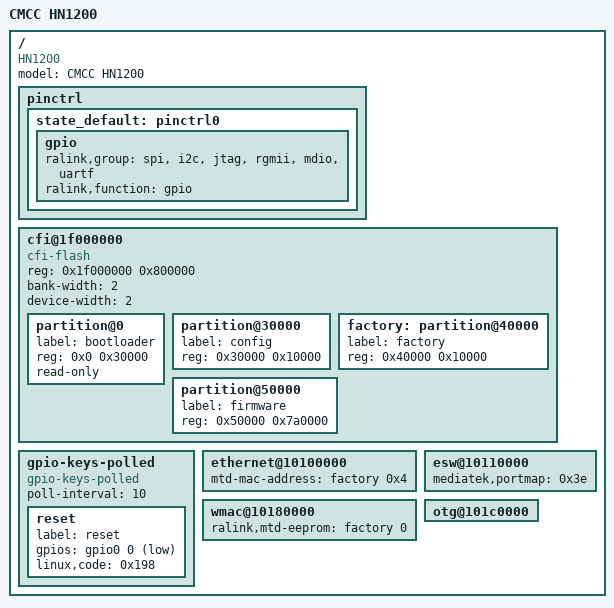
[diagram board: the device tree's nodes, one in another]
/dts-v1/;

/include/ "rt3050.dtsi"

/ {
	compatible = "HN1200", "ralink,rt3050-soc";
	model = "CMCC HN1200";

	pinctrl {
		state_default: pinctrl0 {
			gpio {
				ralink,group = "spi", "i2c", "jtag", "rgmii", "mdio", "uartf";
				ralink,function = "gpio";
			};
		};
	};

	cfi@1f000000 {
		compatible = "cfi-flash";
		reg = <0x1f000000 0x800000>;

		bank-width = <2>;
		device-width = <2>;
		#address-cells = <1>;
		#size-cells = <1>;

		partition@0 {
			label = "bootloader";
			reg = <0x0 0x30000>;
			read-only;
		};

		partition@30000 {
			label = "config";
			reg = <0x30000 0x10000>;
		};

		factory: partition@40000 {
			label = "factory";
			reg = <0x40000 0x10000>;
		};

		partition@50000 {
			label = "firmware";
			reg = <0x50000 0x7a0000>;
		};
	};

	gpio-keys-polled {
		compatible = "gpio-keys-polled";
		#address-cells = <1>;
		#size-cells = <0>;
		poll-interval = <10>;

		reset {
			label = "reset";
			gpios = <&gpio0 0 1>;
			linux,code = <0x198>;
		};
	};

	ethernet@10100000 {
		mtd-mac-address = <&factory 0x4>;
	};

	esw@10110000 {
		mediatek,portmap = <0x3e>;
	};

	wmac@10180000 {
		ralink,mtd-eeprom = <&factory 0>;
	};

	otg@101c0000 {
		status = "okay";
	};
};
